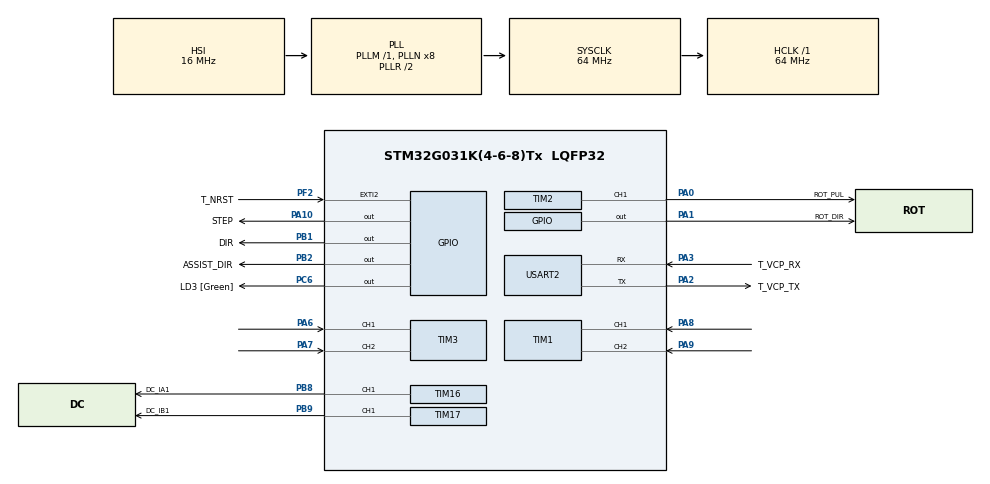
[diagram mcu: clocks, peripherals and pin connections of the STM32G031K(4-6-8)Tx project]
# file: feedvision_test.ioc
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Mcu.Family=STM32G0
Mcu.Name=STM32G031K(4-6-8)Tx
Mcu.Package=LQFP32
NVIC.TIM14_IRQn=true\:0\:0\:false\:false\:true\:true\:true\:true
NVIC.USART2_IRQn=true\:2\:0\:true\:false\:true\:true\:true\:true
PA0.GPIO_Label=ROT_PUL
PA0.GPIO_Speed=GPIO_SPEED_FREQ_HIGH
PA0.Signal=S_TIM2_CH1
PA1.GPIO_Label=ROT_DIR
PA1.GPIO_Speed=GPIO_SPEED_FREQ_HIGH
PA1.Signal=GPIO_Output
PA10.GPIO_Label=STEP
PA10.GPIO_Speed=GPIO_SPEED_FREQ_HIGH
PA10.Signal=GPIO_Output
PA13.GPIO_Label=T_JTMS
PA13.Mode=Serial_Wire
PA13.Signal=SYS_SWDIO
PA14-BOOT0.GPIO_Label=T_JTCK
PA14-BOOT0.Mode=Serial_Wire
PA14-BOOT0.Signal=SYS_SWCLK
PA2.GPIO_Label=T_VCP_TX
PA2.GPIO_PuPd=GPIO_PULLUP
PA2.Mode=Asynchronous
PA2.Signal=USART2_TX
PA3.GPIO_Label=T_VCP_RX
PA3.GPIO_PuPd=GPIO_PULLUP
PA3.Mode=Asynchronous
PA3.Signal=USART2_RX
PA6.GPIO_PuPd=GPIO_PULLUP
PA6.Signal=S_TIM3_CH1
PA7.GPIO_PuPd=GPIO_PULLUP
PA7.Signal=S_TIM3_CH2
PA8.GPIO_PuPd=GPIO_PULLUP
PA8.Signal=S_TIM1_CH1
PA9.GPIO_PuPd=GPIO_PULLUP
PA9.Signal=S_TIM1_CH2
# Yardımcı çift (2x NEMA17 + 2. TB6600): PB0 = LPTIM1_OUT (AF5) PUL, PB2 = GPIO DIR.
# Kodda PB0 açılışta/durdurmada GPIO LOW, "assist" komutunda AF5'e geçer (main.c assist_*).
PB0.GPIO_Label=ASSIST_PUL
PB0.GPIO_Speed=GPIO_SPEED_FREQ_HIGH
PB0.Signal=LPTIM1_OUT
PB1.GPIO_Label=DIR
PB1.GPIO_Speed=GPIO_SPEED_FREQ_HIGH
PB1.Signal=GPIO_Output
PB2.GPIO_Label=ASSIST_DIR
PB2.GPIO_Speed=GPIO_SPEED_FREQ_HIGH
PB2.Signal=GPIO_Output
PB8.GPIO_Label=DC_IA1
PB8.GPIO_Speed=GPIO_SPEED_FREQ_HIGH
PB8.Signal=S_TIM16_CH1
PB9.GPIO_Label=DC_IB1
PB9.GPIO_Speed=GPIO_SPEED_FREQ_HIGH
PB9.Signal=S_TIM17_CH1
PC14-OSC32_IN\ (PC14).Mode=LSE-External-Oscillator
PC14-OSC32_IN\ (PC14).Signal=RCC_OSC32_IN
PC15-OSC32_OUT\ (PC15).Mode=LSE-External-Oscillator
PC15-OSC32_OUT\ (PC15).Signal=RCC_OSC32_OUT
PC6.GPIO_Label=LD3 [Green]
PC6.Signal=GPIO_Output
PF2\ -\ NRST.GPIO_Label=T_NRST
PF2\ -\ NRST.Signal=GPXTI2
ProjectManager.HeapSize=0x200
ProjectManager.StackSize=0x400
ProjectManager.TargetToolchain=STM32CubeIDE
RCC.ADCFreq_Value=64000000
RCC.AHBFreq_Value=64000000
RCC.CortexFreq_Value=64000000
RCC.EXTERNAL_CLOCK_VALUE=12288000
RCC.HCLKFreq_Value=64000000
RCC.HSE_VALUE=8000000
RCC.HSI_VALUE=16000000
RCC.LPTIM1CLockSelection=RCC_LPTIM1CLKSOURCE_PCLK1
RCC.SYSCLKFreq_VALUE=64000000
RCC.SYSCLKSource=RCC_SYSCLKSOURCE_PLLCLK
RCC.VCOOutputFreq_Value=128000000
SH.S_TIM1_CH1.0=TIM1_CH1,Encoder_Interface
SH.S_TIM1_CH2.0=TIM1_CH2,Encoder_Interface
SH.S_TIM3_CH1.0=TIM3_CH1,Encoder_Interface
SH.S_TIM3_CH2.0=TIM3_CH2,Encoder_Interface
SH.S_TIM2_CH1.0=TIM2_CH1,PWM Generation1 CH1
SH.S_TIM16_CH1.0=TIM16_CH1,PWM Generation1 CH1
SH.S_TIM17_CH1.0=TIM17_CH1,PWM Generation1 CH1
# LPTIM1: yardımcı çift PUL (PB0), PCLK1 64 MHz / 64 = 1 MHz tick. ARR/CMP çalışırken
# main.c assist_write_delay() ile yazılır; PRELOAD (UpdateMode=ENDOFPERIOD) glitch'siz güncelleme için şart.
LPTIM1.ClockPrescaler=LPTIM_PRESCALER_DIV64
LPTIM1.TriggerSource=LPTIM_TRIGSOURCE_SOFTWARE
LPTIM1.UpdateMode=LPTIM_UPDATE_ENDOFPERIOD
TIM1.EncoderMode=TIM_ENCODERMODE_TI12
TIM1.IC1Filter=15
TIM1.IC2Filter=15
# TIM14: step darbe üreteci (base/kesme modu) - 22-09-2026'da TIM16'dan
# buraya taşındı, TIM16 DC motor PWM'e ayrıldığı için (backlog #109).
TIM14.Period=499
TIM14.Prescaler=63
# TIM16/TIM17: DC motor PWM (L9110 hız kontrolü), 1 kHz (Prescaler=63,
# Period=999 -> 1 MHz tick / 1000 = 1 kHz). Frekans seçimi datasheet değeri
# DEĞİL, bkz. docs/protocol.md "DC motor PWM" notu.
TIM16.Period=999
TIM16.Prescaler=63
TIM16.Channel-PWM Generation1 CH1=TIM_CHANNEL_1
TIM16.Pulse-PWM Generation1 CH1=0
TIM17.Period=999
TIM17.Prescaler=63
TIM17.Channel-PWM Generation1 CH1=TIM_CHANNEL_1
TIM17.Pulse-PWM Generation1 CH1=0
# TIM2: dönüş ekseni PUL (NEMA17 + TB6600), PA0/TIM2_CH1 donanım PWM, 1 MHz tick.
# Period=999 sadece başlangıç değeri; çalışırken main.c rot_apply_delay() ARR/CCR'yi
# delay_us'e göre yazar (CCR=0 -> darbe yok). ARR preload açık: glitch'siz güncelleme.
TIM2.AutoReloadPreload=TIM_AUTORELOAD_PRELOAD_ENABLE
TIM2.Channel-PWM Generation1 CH1=TIM_CHANNEL_1
TIM2.Period=999
TIM2.Prescaler=63
TIM2.Pulse-PWM Generation1 CH1=0
TIM3.EncoderMode=TIM_ENCODERMODE_TI12
TIM3.IC1Filter=15
TIM3.IC2Filter=15
USART2.VirtualMode-Asynchronous=VM_ASYNC
USART2.WordLength=WORDLENGTH_8B
VP_LPTIM1_VS_LPTIM_counterModeInternalClock.Mode=Counts__internal_clock_event_00
VP_TIM14_VS_ClockSourceINT.Mode=Enable_Timer
VP_TIM16_VS_ClockSourceINT.Mode=Enable_Timer
VP_TIM17_VS_ClockSourceINT.Mode=Enable_Timer
VP_TIM2_VS_ClockSourceINT.Mode=Internal
board=NUCLEO-G031K8

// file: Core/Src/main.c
/* USER CODE BEGIN Header */
/**
  ******************************************************************************
  * @file           : main.c
  * @brief          : Main program body
  ******************************************************************************
  * @attention
  *
  * Copyright (c) 2026 STMicroelectronics.
  * All rights reserved.
  *
  * This software is licensed under terms that can be found in the LICENSE file
  * in the root directory of this software component.
  * If no LICENSE file comes with this software, it is provided AS-IS.
  *
  ******************************************************************************
  */
/* USER CODE END Header */
#include "main.h"

/* USER CODE BEGIN Includes */

#include <string.h>
#include <stdio.h>
#include <stdlib.h>

/* USER CODE END Includes */

/* USER CODE BEGIN PD */

/* --- Pin tanımları -------------------------------------------------------
 * CubeMX'te User Label yazdıysan bu tanımlar zaten üretilmiştir ve aşağıdaki
 * #ifndef blokları atlanır. Yazmadıysan bunlar devreye girer.               */
#ifndef STEP_Pin
  #define STEP_Pin            GPIO_PIN_10
  #define STEP_GPIO_Port      GPIOA
#endif
#ifndef DIR_Pin
  #define DIR_Pin             GPIO_PIN_1
  #define DIR_GPIO_Port       GPIOB
#endif
#ifndef DC_IA1_Pin
  #define DC_IA1_Pin          GPIO_PIN_8
  #define DC_IA1_GPIO_Port    GPIOB
#endif
#ifndef DC_IB1_Pin
  #define DC_IB1_Pin          GPIO_PIN_9
  #define DC_IB1_GPIO_Port    GPIOB
#endif
/* Dönüş ekseni (NEMA17 + TB6600): PUL = PA0 (D/A0, TIM2_CH1 PWM), DIR = PA1 (A1, GPIO) */
#ifndef ROT_PUL_Pin
  #define ROT_PUL_Pin         GPIO_PIN_0
  #define ROT_PUL_GPIO_Port   GPIOA
#endif
#ifndef ROT_DIR_Pin
  #define ROT_DIR_Pin         GPIO_PIN_1
  #define ROT_DIR_GPIO_Port   GPIOA
#endif
/* Yardımcı çift (2x NEMA17 paralel + 2. TB6600): PUL = PB0 (D6, LPTIM1_OUT AF5), DIR = PB2 (D7, GPIO) */
#ifndef ASSIST_PUL_Pin
  #define ASSIST_PUL_Pin       GPIO_PIN_0
  #define ASSIST_PUL_GPIO_Port GPIOB
#endif
#ifndef ASSIST_DIR_Pin
  #define ASSIST_DIR_Pin       GPIO_PIN_2
  #define ASSIST_DIR_GPIO_Port GPIOB
#endif

/* --- Step motor sınırları ------------------------------------------------
 * delay = iki darbe arasındaki toplam süre (mikrosaniye).
 * Alt sınır 20 us: DM556 datasheet'i 200 kHz'e (5 us periyot) kadar cevap
 * verdiğini söylüyor; biz 4 kat güvenlik payı bırakıp 50 kHz'de duruyoruz.
 * Üst sınır 60000 us: timer 1 MHz'de çalıştığı için yarım periyot 65535'i
 * (16 bit sayacın tavanı) geçemez.                                          */
#define STEP_MIN_DELAY_US     20U
#define STEP_MAX_DELAY_US     60000U

/* Rampa (hızlanma/yavaşlama) başlangıç/bitiş gecikmesi: sıfırdan bu HIZLA
 * (yani bu kadar YAVAŞ bir delay ile) başlar, "accel" kadar adımda hedef
 * hıza (komuttaki delay'e) çıkar; hareketin son "accel" adımında da aynı
 * şekilde bu hıza geri iner. Motor+yük değişirse SAHADA burayı ayarla —
 * çok küçük kalırsa yine sıfırdan hızlı kalkış = step kaybı riski sürer,
 * çok büyük kalırsa rampa gereksiz uzun sürer. */
#define STEP_RAMP_START_DELAY_US  2000U

/* --- Encoder / mesafe hesabı sabitleri -----------------------------------
 * SAHADA DOĞRULA: ENC_PPR encoder etiketinden, WHEEL_DIAMETER_MM kumpasla.  */
#define ENC_PPR               600.0f     /* encoder etiketinde yazan darbe/tur */
#define ENC_EDGE_MULTIPLIER   4.0f       /* timer A ve B'nin 4 kenarını da sayar */
#define WHEEL_DIAMETER_MM     40.0f      /* VARSAYIM - gerçek tekerlekle güncelle */

/* --- PC'ye durum gönderme hızı ------------------------------------------- */
#define STATUS_PERIOD_MS      50U        /* 50 ms = saniyede 20 satır */

/* --- Seri porttan gelen komut satırı tamponu ----------------------------- */
#define RX_LINE_MAX            96

/* --- DC motor PWM (L9110 hız kontrolü, backlog #109) ---------------------
 * TIM16/TIM17'yi 1 MHz tick'e böldük (Prescaler=63, 64 MHz APB/64), periyot
 * 1000 tık = 1 ms -> 1 kHz PWM frekansı. 1 kHz seçimi L9110 datasheet'inde
 * yazan bir "optimal PWM frekansı" değil (datasheet'te böyle bir değer YOK,
 * sadece VCC/akım limitleri var) - hobi-seviye DC motor sürücülerinde yaygın
 * kullanılan, motorun elektriksel zaman sabitine göre güvenli bir orta değer.
 * SAHADA DOĞRULA: çok düşük duty'de motor gerçekten dönüyor mu (minimum
 * çalışır duty), ses/ısınma sorunlu mu - gerekirse bu tek satırı değiştir. */
#define DC_PWM_PRESCALER        63U    /* 64 MHz / 64 = 1 MHz tick (1 us) */
#define DC_PWM_PERIOD_TICKS    999U    /* 1000 tık = 1 ms periyot -> 1 kHz PWM */
#define DC_SPEED_DEFAULT_PCT   100U    /* "speed" alanı yoksa eski davranış: tam hız */

/* --- Dönüş ekseni (rot): NEMA17 + TB6600, TIM2_CH1 donanım PWM -------------
 * TIM2 de 1 MHz tick (Prescaler=63), ama burada periyot = delay_us: ARR=delay-1,
 * CCR=delay/2 (%50 doluluk). Dönüş sürekli ve mesafesiz olduğu için darbe SAYMAYA
 * gerek yok -> darbeyi donanım üretir (kesmesiz, jitter'sız). Durdurmak = CCR=0
 * (PWM1'de CCR=0 çıkışı sürekli LOW tutar).
 * delay_us = iki darbe arası süre (step komutundaki delay ile aynı anlam).
 * Alt sınır 100 us = 10 kHz: %50 doluluk -> darbe genişliği 50 us. TB6600 satıcı
 * beyanı üst frekans 50 kHz (Joy-IT SBC-MD-TB6600 datasheet) -> 5 kat pay.
 * Üst sınır 60000 us: RPi ile sabit sözleşme (TIM2 32 bit, teknik olarak daha
 * yavaşı mümkün ama iki taraf senkron kalsın diye YÜKSELTİLMEDİ).
 * Sınırların dışı step komutundaki gibi sessizce kırpılır. */
#define ROT_MIN_DELAY_US        100U
#define ROT_MAX_DELAY_US        60000U
#define ROT_PWM_PRESCALER       63U    /* 64 MHz / 64 = 1 MHz tick (1 us) */
#define ROT_PWM_INIT_PERIOD_TICKS 999U /* sadece başlangıç; çalışırken delay_us'den yazılır */

/* "cw" = motorun MİL UCUNA bakınca saat yönü. DIR pininin hangi seviyesinin cw
 * olduğu kablolamaya (motor bobin polaritesi) bağlı, SAHADA DOĞRULA: ters
 * dönüyorsa SADECE bu satırı GPIO_PIN_RESET yap. */
#define ROT_CW_DIR_LEVEL        GPIO_PIN_SET
#define ROT_CCW_DIR_LEVEL       ((ROT_CW_DIR_LEVEL == GPIO_PIN_SET) ? GPIO_PIN_RESET : GPIO_PIN_SET)

/* Yazılımsal rampa (yumuşak kalkış). Sebep: 100 us (10 kHz = 3.125 tur/s, 1/16
 * mikroadımda) sıfırdan ani başlangıçta NEMA17 senkronu kaybedip dönmeyebilir.
 * Frekans domaininde sabit ivme: START_DELAY'den (1000 us = 1 kHz = ~19 dev/dk)
 * başlar, ACCEL kadar darbe/s^2 ile hedefe çıkar. Hedef START'tan yavaşsa
 * rampa yok, doğrudan hedefte başlar. Hız değişimi ve yön değişimi de aynı
 * rampayı kullanır (yön değişiminde önce START'a iner, DIR çevrilir, tekrar
 * çıkar). stop/reset/bye ise ANINDA keser (güvenlik; konum takibi yok, adım
 * kaybı bir sorun değil). Yük bilinmiyor: SAHADA ayarla - motor kalkışta
 * takılıyorsa ACCEL'i düşür / START_DELAY'i büyüt. */
#define ROT_RAMP_START_DELAY_US     1000U
#define ROT_RAMP_ACCEL_HZ_PER_S     10000U   /* 1 kHz -> 10 kHz yaklaşık 0.9 s */
#define ROT_RAMP_TICK_MS            10U      /* rampa en sık bu aralıkla güncellenir */

/* --- Yardımcı çift (assist): 2x NEMA17 paralel + 2. TB6600, LPTIM1_OUT donanım PWM ---
 * Besleme ekseninde NEMA23'e (step) çubuğa yardım eden iki NEMA17. İki motor aynı
 * yönde döner, tek bir PUL/DIR çifti ikisini birden sürer. Hızı step'ten BAĞIMSIZ,
 * kendi delay'i vardır (oran/çarpan hesabı yok).
 * Darbeyi LPTIM1 donanımı üretir (kesmesiz, jitter'sız; TIM14/encoder/USART2'ye etkisi
 * yok). TIM1/2/3/14/16/17 dolu; PB0'a bağlanabilen tek boş sayaç LPTIM1
 * (PB0 = LPTIM1_OUT, AF5).
 * LPTIM1 çekirdek saati PCLK1 = 64 MHz, önbölücü /64 -> 1 MHz (1 tık = 1 us).
 * ARR = delay-1, çıkış periyodun SONUNDA yüksek: CMP = ARR - delay/2 -> %50 doluluk,
 * darbe genişliği delay/2 (alt sınırda 50 us; TB6600 için >=10 us güvenli minimum).
 * Alt/üst sınır rot ile aynı; ARR 16 bit olduğu için 65536 us'nin altında kalmak şart.
 * Sınırların dışı step/rot komutundaki gibi sessizce kırpılır. */
#define ASSIST_MIN_DELAY_US     100U
#define ASSIST_MAX_DELAY_US     60000U
#define ASSIST_LPTIM_CFGR       (LPTIM_CFGR_PRESC_1 | LPTIM_CFGR_PRESC_2 | LPTIM_CFGR_PRELOAD)  /* /64, değerler periyot sonunda devreye girer */
#define ASSIST_HW_WAIT_LOOPS    20000U   /* ARROK/CMPOK bayrağı için sınırlı bekleme (başlatmada) */
#define ASSIST_HW_TIMEOUT_MS    250U     /* bayrak/periyot sonu bu sürede gelmezse eksen durdurulur (en uzun periyot 60 ms) */

/* "cw" = ortak dönüş yönü. DIR seviyesi kablolamaya bağlı, SAHADA DOĞRULA:
 * ters dönüyorsa SADECE bu satırı GPIO_PIN_RESET yap. */
#define ASSIST_CW_DIR_LEVEL     GPIO_PIN_SET
#define ASSIST_CCW_DIR_LEVEL    ((ASSIST_CW_DIR_LEVEL == GPIO_PIN_SET) ? GPIO_PIN_RESET : GPIO_PIN_SET)

/* Rampa rot ile aynı (ayrı ayarlanabilsin diye ayrı tanım). */
#define ASSIST_RAMP_START_DELAY_US  1000U
#define ASSIST_RAMP_ACCEL_HZ_PER_S  10000U
#define ASSIST_RAMP_TICK_MS         10U

/* USER CODE END PD */

TIM_HandleTypeDef htim1;
TIM_HandleTypeDef htim2;    /* dönüş ekseni PUL (donanım PWM) - PA0/TIM2_CH1 */
TIM_HandleTypeDef htim3;
TIM_HandleTypeDef htim14;   /* step darbe üreteci (base/kesme modu) - eskiden TIM16'daydı */
TIM_HandleTypeDef htim16;   /* DC motor PWM - IA1/PB8 */
TIM_HandleTypeDef htim17;   /* DC motor PWM - IB1/PB9 */

UART_HandleTypeDef huart2;

/* USER CODE BEGIN PV */

/* --- Step darbe üreteci durumu ------------------------------------------
 * "volatile": bu değişkenleri hem ana döngü hem kesme (interrupt) değiştiriyor,
 * derleyiciye "değeri önbelleğe alma, her seferinde bellekten oku" diyoruz.  */
typedef struct {
  volatile uint32_t remaining;  /* atılmayı bekleyen darbe sayısı */
  volatile uint8_t  level;      /* STEP pini şu an 1 mi 0 mı */
  volatile uint8_t  running;    /* 1 = hareket sürüyor */

  /* --- Rampa (hızlanma/yavaşlama) durumu ---------------------------------
   * "delay" artık tek bir sabit değer değil, hareket boyunca değişebiliyor:
   * ilk "accel_steps" adımda start_delay'den cruise_delay'e iner (hızlanma),
   * ortada cruise_delay'de sabit kalır, son "accel_steps" adımda tekrar
   * start_delay'e çıkar (yavaşlama). accel_steps=0 ise rampa YOK, eski
   * davranış: baştan sona sabit cruise_delay (geriye dönük uyumlu). */
  uint32_t total_steps;     /* step_start()'a verilen toplam adım (rampa oranı için) */
  uint32_t cruise_delay_us; /* hedef/komut edilen sabit hız */
  uint32_t start_delay_us;  /* rampa başlangıç/bitiş gecikmesi (yavaş, güvenli) */
  uint32_t accel_steps;     /* kaç adımda hızlanılıp/yavaşlanılacağı */
} step_generator_t;

static step_generator_t g_step = {0, 0, 0};

/* --- Encoder okuma durumu ------------------------------------------------
 * Timer'ın sayacı 16 bit (0..65535) ve dolunca başa dönüyor. Toplam mesafeyi
 * kaybetmemek için her okumada FARKI alıp 32 bitlik bir toplayıcıda biriktiriyoruz. */
typedef struct {
  TIM_HandleTypeDef *htim;
  uint16_t           last_raw;  /* en son okunan 16 bit sayaç değeri */
  int32_t            total;     /* başlangıçtan beri toplam sayım (işaretli) */
} encoder_t;

static encoder_t g_enc1;        /* TIM1 - motorlu tekerlek */
static encoder_t g_enc2;        /* TIM3 - boşta tekerlek */

/* --- DC motor durumu: 0=dur, 1=ileri, 2=geri; hız 0-100 (duty %) --------- */
static uint8_t g_dc_state = 0;
static uint8_t g_dc_speed = 0;

/* --- Dönüş ekseni (rot) durumu -------------------------------------------
 * Hepsi ana döngü bağlamında (process_command + rot_service) değişir, kesme
 * dokunmaz -> volatile gerekmez. */
typedef struct {
  uint8_t  state;            /* komut edilen yön: 0=dur, 1=cw, 2=ccw (durumdaki "rot") */
  uint8_t  phys_state;       /* DIR pininin şu an gerçekten ayarlı olduğu yön (0=henüz ayarlanmadı) */
  uint8_t  pulsing;          /* 1 = PUL çıkışı darbe üretiyor */
  uint8_t  reversing;        /* 1 = yön değişimi için START hızına yavaşlıyor */
  uint32_t target_delay_us;  /* komut edilen (kırpılmış) hedef delay (durumdaki "rdelay") */
  uint32_t cur_delay_us;     /* o anki gerçek darbe periyodu (rampa ortasında hedeften yavaş) */
  uint32_t last_ramp_ms;     /* rampanın son güncellendiği HAL_GetTick */
} rot_axis_t;

static rot_axis_t g_rot = {0, 0, 0, 0, 0, 0, 0};

/* --- Yardımcı çift (assist) durumu ----------------------------------------
 * rot ile aynı alanlar + LPTIM yazma bayrağı beklemesi. Kesme dokunmaz (LPTIM
 * kesmesi kapalı) -> volatile gerekmez. */
typedef struct {
  uint8_t  state;            /* komut edilen yön: 0=dur, 1=cw, 2=ccw (durumdaki "assist") */
  uint8_t  phys_state;       /* DIR pininin şu an gerçekten ayarlı olduğu yön (0=henüz ayarlanmadı) */
  uint8_t  pulsing;          /* 1 = LPTIM1 çalışıyor, PB0 darbe üretiyor */
  uint8_t  reversing;        /* 1 = yön değişimi için START hızına yavaşlıyor */
  uint8_t  reg_pending;      /* 1 = ARR/CMP yazıldı, ARROK+CMPOK bayrakları bekleniyor */
  uint32_t target_delay_us;  /* komut edilen (kırpılmış) hedef delay (durumdaki "adelay") */
  uint32_t cur_delay_us;     /* o anki gerçek darbe periyodu */
  uint32_t last_ramp_ms;     /* rampanın son güncellendiği HAL_GetTick */
  uint32_t reg_write_ms;     /* ARR/CMP son yazıldığı HAL_GetTick (zaman aşımı için) */
} assist_axis_t;

static assist_axis_t g_assist = {0, 0, 0, 0, 0, 0, 0, 0, 0};

/* --- Seri port alım tamponları ------------------------------------------ */
static uint8_t           g_rx_byte;                    /* kesmede tek tek gelen karakter */
static char               g_rx_line[RX_LINE_MAX];      /* birikmekte olan satır */
static volatile uint16_t g_rx_length = 0;
static char               g_command[RX_LINE_MAX];      /* tamamlanmış komut satırı */
static volatile uint8_t  g_command_ready = 0;

/* --- Durum gönderme zamanlayıcısı --------------------------------------- */
static uint32_t g_last_status_ms = 0;

/* --- LED ile bağlantı doğrulaması ----------------------------------------
 * host_confirmed: Pi/Mac'ten geçerli bir komut alınca 1 olur. LED'i
 * yavaş/hızlı yanıp söndürmek için kullanılır (bkz. USER CODE 3): yavaş =
 * "firmware çalışıyor ama kimse konuşmadı / bağlantı koptu", hızlı = "gerçek
 * bir komut alındı, karşı taraf bağlı". Host bağlantının koptuğuna karar
 * verince "bye" komutunu gönderir (bkz. process_command) — bu bayrağı tekrar
 * 0'a çeker, LED yavaş moda döner (22-09-2026, LED tek-yön latch düzeltmesi). */
static volatile uint8_t g_host_confirmed = 0;
static uint16_t          g_led_tick = 0;

/* USER CODE END PV */

void SystemClock_Config(void);
static void MX_GPIO_Init(void);
static void MX_TIM1_Init(void);
static void MX_LPTIM1_Init(void);
static void MX_TIM2_Init(void);
static void MX_TIM3_Init(void);
static void MX_TIM14_Init(void);
static void MX_TIM16_Init(void);
static void MX_TIM17_Init(void);
static void MX_USART2_UART_Init(void);
/* USER CODE BEGIN PFP */

/* --- Encoder fonksiyonları --- */
static void     encoder_init(encoder_t *e, TIM_HandleTypeDef *htim);   // encoder'ı sıfırdan başlatır (donanım sayacını çalıştırır)
static void     encoder_update(encoder_t *e);                          // sayacı okuyup toplam mesafeye ekler (periyodik çağrılır)
static void     encoder_reset(encoder_t *e);                           // sayacı ve toplamı 0'a resetler
static int32_t  encoder_to_micrometers(int32_t count);                 // ham sayımı mikrometreye (mm'nin 1000'de biri) çevirir

/* --- Step motor fonksiyonları --- */
static void     step_start(uint8_t dir, uint32_t count, uint32_t delay_us, uint32_t accel_steps);  // step motoru başlatır: yön + kaç adım + ne hızda + kaç adımda hızlan/yavaşla
static uint32_t step_delay_for_remaining(uint32_t remaining);  // rampanın o anki fazına göre gecikme hesaplar
static void     step_stop(void);                                              // step motoru anında durdurur

/* --- DC motor fonksiyonu --- */
static uint16_t dc_duty_ticks(uint8_t speed_pct);       // 0-100 yüzdeyi timer CCR tık değerine çevirir
static void     dc_set(uint8_t state, uint8_t speed_pct);  // DC motoru ileri/geri/dur + hız (PWM duty %) durumuna sokar

/* --- Dönüş ekseni (NEMA17 + TB6600) fonksiyonları --- */
static uint32_t rot_next_delay(uint32_t cur_us, uint32_t goal_us, uint32_t dt_ms);  // rampada bir sonraki darbe periyodunu hesaplar (saf fonksiyon)
static void     rot_apply_delay(uint32_t delay_us);                                 // TIM2 periyodunu/dolulugunu delay_us'e ayarlar
static void     rot_begin(uint8_t dir_state);                                       // DIR'i ayarlayıp darbeyi rampa başlangıç hızıyla başlatır
static void     rot_halt_pulses(void);                                              // PUL çıkışını anında LOW'a çeker (durum alanlarına dokunmaz)
static void     rot_stop(void);                                                     // dönüş eksenini anında durdurur (stop/reset/bye de bunu çağırır)
static void     rot_command(uint8_t dir_state, uint32_t delay_us);                  // "rot" komutu: başlat / hız değiştir / yön değiştir
static void     rot_service(void);                                                  // ana döngüden periyodik çağrılır: rampayı ilerletir

/* --- Yardımcı çift (2x NEMA17 + 2. TB6600, LPTIM1) fonksiyonları --- */
static uint32_t ramp_next_delay(uint32_t cur_us, uint32_t goal_us, uint32_t dt_ms, uint32_t accel_hz_per_s);  // rampada bir sonraki darbe periyodu (saf fonksiyon, rot ve assist ortak)
static void     assist_pul_gpio_low(void);                                          // PB0'ı GPIO çıkışı yapıp anında LOW'a çeker
static void     assist_pul_af(void);                                                // PB0'ı LPTIM1_OUT (AF5) yapar
static void     assist_write_delay(uint32_t delay_us);                              // LPTIM1 ARR/CMP'yi delay_us'e göre yazar
static uint8_t  assist_wait_flags(uint32_t mask);                                   // ISR bayraklarını sınırlı süre bekler (1=geldi)
static void     assist_halt_pulses(void);                                           // PB0 LOW + LPTIM1 reset (durum alanlarına dokunmaz)
static void     assist_stop(void);                                                  // yardımcı çifti anında durdurur (stop/reset/bye de bunu çağırır)
static uint8_t  assist_begin(uint8_t dir_state);                                    // DIR'i ayarlayıp darbeyi rampa başlangıç hızıyla başlatır (0=donanım hatası)
static uint8_t  assist_command(uint8_t dir_state, uint32_t delay_us);               // "assist" komutu: başlat / hız değiştir / yön değiştir (0=donanım hatası)
static void     assist_service(void);                                               // ana döngüden periyodik çağrılır: rampayı ilerletir

/* --- Seri port (UART) fonksiyonları --- */
static void     uart_send(const char *s);              // bir metni Mac'e (seri port üzerinden) gönderir
static void     send_status(void);                      // encoder/motor durumunu JSON olarak Mac'e yollar
static void     process_command(const char *line);      // Mac'ten gelen bir JSON komut satırını yorumlayıp uygular

/* --- JSON okuma yardımcıları (kütüphanesiz, elle yazılmış basit ayrıştırıcı) --- */
static int      json_read_int(const char *json, const char *key, int32_t *out);                 // JSON'dan bir sayı değeri çeker (örn: "delay":500)
static int      json_read_str(const char *json, const char *key, char *out, uint16_t out_size);  // JSON'dan bir metin değeri çeker (örn: "cmd":"step")

/* USER CODE END PFP */

/* USER CODE BEGIN 0 */

/* ==========================================================================
 *  ENCODER  —  sayaç okuma ve mesafeye çevirme
 * ========================================================================== */

static void encoder_init(encoder_t *e, TIM_HandleTypeDef *htim)
{
  e->htim = htim;
  HAL_TIM_Encoder_Start(htim, TIM_CHANNEL_ALL);   /* donanım saymaya başlasın */
  __HAL_TIM_SET_COUNTER(htim, 0);
  e->last_raw = 0;
  e->total    = 0;
}

/* Ana döngüde periyodik çağrılır. 16 bit sayacın taşmasını doğru şekilde işler. */
static void encoder_update(encoder_t *e)
{
  uint16_t raw = (uint16_t)__HAL_TIM_GET_COUNTER(e->htim);

  /* İki 16 bit sayının farkını int16_t olarak almak, sayaç 65535'ten 0'a
   * atladığında da doğru sonucu verir (ör: 5 - 65530 = 11, geriye değil ileriye). */
  int16_t diff = (int16_t)(raw - e->last_raw);

  e->last_raw  = raw;
  e->total    += (int32_t)diff;
}

static void encoder_reset(encoder_t *e)
{
  __HAL_TIM_SET_COUNTER(e->htim, 0);
  e->last_raw = 0;
  e->total    = 0;
}

/* --------------------------------------------------------------------------
 *  5 mm'lik mesafe nasıl hesaplanıyor  (asıl istenen mantık burada)
 * --------------------------------------------------------------------------
 *  1) Encoder bir turda kaç sayım üretir?
 *        counts_per_rev = ENC_PPR * 4 = 600 * 4 = 2400
 *     ("* 4" nereden geliyor: timer'ı "Encoder Mode TI1 and TI2" kurduk, yani
 *      A kanalının hem yükselen hem düşen kenarını, B kanalının da ikisini
 *      sayıyor. Böylece çözünürlük 4 katına çıkıyor.)
 *
 *  2) Tekerlek bir turda kaç mm yol alır?
 *        circumference_mm = pi * WHEEL_DIAMETER_MM = 3.14159 * 40.0 = 125.664 mm
 *
 *  3) Bir sayım kaç mm eder?
 *        mm_per_count = 125.664 / 2400 = 0.05236 mm  (yani 52.36 mikrometre)
 *
 *  4) 5 mm ilerlemek için kaç sayım gerekir?
 *        5.0 / 0.05236 = 95.5 count
 *     Yani "5 mm ilerledi" demek icin encoder sayacinin ~96 artmasi lazim.
 *     Bu, 5 mm'lik bir olcumu +/- 0.05 mm hassasiyetle gorebiliyoruz demek —
 *     bu uygulama icin fazlasiyla yeterli.
 *
 *  5) Patinaj (kayma) tespiti:
 *        Encoder 1 = motorlu tekerlek, Encoder 2 = bosta klavuz tekerlek.
 *        Ikisi ayni cubugu olcuyor. Aralarindaki mm farki = kayan miktar.
 *        Fark buyurse cubuk motorun altinda patinaj yapiyor demektir.
 *
 *  NOT: WHEEL_DIAMETER_MM su an 40.0 mm VARSAYIM. Gercek tekerlek gelince
 *       olcup degistir, yoksa buradaki tum mm degerleri orantili sekilde
 *       yanlis olur.
 * -------------------------------------------------------------------------- */

/* Sayımı mikrometreye çevirir.
 * Neden mm değil mikrometre: CubeIDE varsayılan ayarında printf ondalık sayı
 * basamıyor (%f çöp üretir). Tam sayı gönderip PC'de 1000'e bölüyoruz. */
static int32_t encoder_to_micrometers(int32_t count)
{
  const float counts_per_rev   = ENC_PPR * ENC_EDGE_MULTIPLIER;         /* 2400 */
  const float circumference_um = 3.14159265f * WHEEL_DIAMETER_MM * 1000.0f; /* 125663.7 um */
  const float um_per_count     = circumference_um / counts_per_rev;     /* 52.36 um */

  return (int32_t)((float)count * um_per_count);
}

/* ==========================================================================
 *  STEP MOTOR  —  TIM14 kesmesi ile sabit hızda darbe üretimi
 *  (22-09-2026: DC motor PWM eklenirken TIM16'dan TIM14'e taşındı - bkz.
 *  main.c başındaki "DC motor PWM" bölümü ve INSA_GUNLUGU.md notu.)
 * ========================================================================== */

/* Şu anki adımda (remaining kaç darbe kaldıysa) kullanılması gereken
 * gecikmeyi hesaplar — rampanın hızlanma/sabit/yavaşlama neresinde
 * olduğumuza bakar. ISR içinden de çağrıldığı için basit tam sayı
 * matematiği dışında bir şey yapmaz (float/bölme dışı ağır işlem yok). */
static uint32_t step_delay_for_remaining(uint32_t remaining)
{
  uint32_t done = g_step.total_steps - remaining;   /* şu ana kadar atılan darbe */

  if (g_step.accel_steps == 0U) {
    return g_step.cruise_delay_us;                  /* rampa yok - eski davranış */
  }
  if (done < g_step.accel_steps) {
    /* Hızlanma: start_delay'den cruise_delay'e doğrusal iniyor. */
    uint32_t span = g_step.start_delay_us - g_step.cruise_delay_us;
    return g_step.start_delay_us - (span * done / g_step.accel_steps);
  }
  if (remaining <= g_step.accel_steps) {
    /* Yavaşlama: cruise_delay'den start_delay'e doğrusal çıkıyor (simetrik). */
    uint32_t span = g_step.start_delay_us - g_step.cruise_delay_us;
    return g_step.start_delay_us - (span * remaining / g_step.accel_steps);
  }
  return g_step.cruise_delay_us;                     /* rampalar arası - sabit hız */
}

/* dir         : 0 veya 1 (DIR pininin seviyesi)
 * count       : atılacak tam darbe sayısı
 * delay_us    : hedef/sabit hız - iki darbe arası toplam süre (mikrosaniye), küçük değer = hızlı
 * accel_steps : hızlanıp yavaşlanacağı adım sayısı (0 = rampasız, eski davranış) */
static void step_start(uint8_t dir, uint32_t count, uint32_t delay_us, uint32_t accel_steps)
{
  if (count == 0U) {
    return;
  }

  /* Kullanıcı saçma bir hız girerse sınırların içine çek */
  if (delay_us < STEP_MIN_DELAY_US) delay_us = STEP_MIN_DELAY_US;
  if (delay_us > STEP_MAX_DELAY_US) delay_us = STEP_MAX_DELAY_US;

  /* Rampa toplam adımın yarısından fazlasını isteyemez (hızlanma+yavaşlama
   * çakışmasın diye) - kısa hareketlerde otomatik küçültülür. */
  if (accel_steps > count / 2U) accel_steps = count / 2U;

  step_stop();   /* önceki hareket varsa temizle */

  /* Yön pinini darbelerden ÖNCE ayarla, sürücünün okuması için 1 ms bekle */
  HAL_GPIO_WritePin(DIR_GPIO_Port, DIR_Pin, dir ? GPIO_PIN_SET : GPIO_PIN_RESET);
  HAL_Delay(1);

  HAL_GPIO_WritePin(STEP_GPIO_Port, STEP_Pin, GPIO_PIN_RESET);
  g_step.level           = 0;
  g_step.remaining       = count;
  g_step.total_steps     = count;
  g_step.cruise_delay_us = delay_us;
  g_step.accel_steps     = accel_steps;
  /* Rampa başlangıcı hedeften daha YAVAŞ olmalı (büyük delay); komut edilen
   * hız zaten rampa başlangıcından yavaşsa (delay_us >= start delay), rampa
   * yapılacak bir şey yok - fiilen accel_steps=0 gibi davranır. */
  g_step.start_delay_us  = (STEP_RAMP_START_DELAY_US > delay_us) ? STEP_RAMP_START_DELAY_US : delay_us;
  g_step.running         = 1;

  /* Timer 1 MHz'de sayıyor (Prescaler=63 ayarladık), yani 1 tık = 1 us.
   * Kesme her YARIM periyotta bir gelecek: bir kesmede pini kaldır, sonrakinde indir.
   * Böylece tam bir darbe delay_us kadar sürer. İlk darbe rampa başlangıç
   * hızıyla (ya da rampasızsa doğrudan cruise hızıyla) başlıyor. */
  __HAL_TIM_SET_AUTORELOAD(&htim14, (step_delay_for_remaining(count) / 2U) - 1U);
  __HAL_TIM_SET_COUNTER(&htim14, 0);
  __HAL_TIM_CLEAR_FLAG(&htim14, TIM_FLAG_UPDATE);  /* bekleyen eski bayrağı sil */

  HAL_TIM_Base_Start_IT(&htim14);
}

static void step_stop(void)
{
  HAL_TIM_Base_Stop_IT(&htim14);
  g_step.running   = 0;
  g_step.remaining = 0;
  g_step.level     = 0;
  HAL_GPIO_WritePin(STEP_GPIO_Port, STEP_Pin, GPIO_PIN_RESET);
}

/* ==========================================================================
 *  DC MOTOR  —  L9110, PWM ile yavaş/hızlı sürüş (22-09-2026, backlog #109)
 * ========================================================================== */

/* L9110'da ayrı bir "enable" pini yok - hız kontrolü aktif yöndeki pine PWM
 * uygulanarak yapılır, diğer pin sabit LOW (duty=0) kalır:
 *   IA1=PWM(duty), IB1=0   -> forward (ileri), hız = duty
 *   IA1=0,         IB1=PWM(duty) -> backward (geri), hız = duty
 *   IA1=0,         IB1=0   -> stop (dur)
 * (İkisini birden aktif/HIGH yapmak yasak - sürücüyü kısa devre eder; bu
 * fonksiyon her zaman diğer kanalı 0'a çektiği için bu durum oluşmaz.)
 * PB8=TIM16_CH1, PB9=TIM17_CH1 - ikisi de artık AF-PWM modunda (bkz.
 * MX_TIM16_Init/MX_TIM17_Init), GPIO_MODE_OUTPUT_PP DEĞİL. */
static uint16_t dc_duty_ticks(uint8_t speed_pct)
{
  if (speed_pct > 100U) speed_pct = 100U;
  /* (period+1) tık = 1 PWM periyodu; speed_pct=100 -> tam periyot (sürekli HIGH) */
  return (uint16_t)(((uint32_t)speed_pct * (DC_PWM_PERIOD_TICKS + 1U)) / 100U);
}

static void dc_set(uint8_t state, uint8_t speed_pct)
{
  uint16_t duty = dc_duty_ticks(speed_pct);

  switch (state) {
    case 1: /* forward */
      __HAL_TIM_SET_COMPARE(&htim16, TIM_CHANNEL_1, duty);
      __HAL_TIM_SET_COMPARE(&htim17, TIM_CHANNEL_1, 0U);
      break;
    case 2: /* backward */
      __HAL_TIM_SET_COMPARE(&htim16, TIM_CHANNEL_1, 0U);
      __HAL_TIM_SET_COMPARE(&htim17, TIM_CHANNEL_1, duty);
      break;
    default: /* stop */
      __HAL_TIM_SET_COMPARE(&htim16, TIM_CHANNEL_1, 0U);
      __HAL_TIM_SET_COMPARE(&htim17, TIM_CHANNEL_1, 0U);
      state = 0;
      speed_pct = 0;
      break;
  }
  g_dc_state = state;
  g_dc_speed = (state == 0U) ? 0U : (speed_pct > 100U ? 100U : speed_pct);
}

/* ==========================================================================
 *  DÖNÜŞ EKSENİ  —  NEMA17 + TB6600, PUL = TIM2_CH1 donanım PWM (PA0)
 *  DIR = PA1 (GPIO). ENA bağlanmaz (TB6600'de ENA aktifse motor serbest kalır,
 *  boş bırakınca sürücü hep aktif = duruşta tutma torku var).
 * ========================================================================== */

/* Rampada bir sonraki darbe periyodu. Sabit İVME frekans domaininde: f = 1e6/delay,
 * f += ACCEL * dt, yeni delay = 1e6/f. goal'a asla taşmaz. Saf fonksiyon (donanıma
 * dokunmaz). Her çağrıda en az 1 us ilerler, yani sonlu adımda goal'a ulaşır. */
static uint32_t ramp_next_delay(uint32_t cur_us, uint32_t goal_us, uint32_t dt_ms, uint32_t accel_hz_per_s)
{
  uint32_t inc;
  uint32_t freq;
  uint32_t next;

  if (cur_us == 0U || cur_us == goal_us) {
    return goal_us;
  }

  inc  = (accel_hz_per_s * dt_ms) / 1000U;            /* bu aralıkta eklenecek frekans (Hz) */
  freq = 1000000U / cur_us;

  if (goal_us < cur_us) {
    /* Hızlan (delay küçülür, frekans artar) */
    next = 1000000U / (freq + inc);
    if (next >= cur_us)  next = cur_us - 1U;           /* tamsayı bölme yüzünden takılmasın */
    if (next < goal_us)  next = goal_us;
  } else {
    /* Yavaşla (delay büyür, frekans azalır) */
    if (inc >= freq) {
      next = goal_us;
    } else {
      next = 1000000U / (freq - inc);
      if (next <= cur_us)  next = cur_us + 1U;
      if (next > goal_us)  next = goal_us;
    }
  }
  return next;
}

static uint32_t rot_next_delay(uint32_t cur_us, uint32_t goal_us, uint32_t dt_ms)
{
  return ramp_next_delay(cur_us, goal_us, dt_ms, ROT_RAMP_ACCEL_HZ_PER_S);
}

/* Darbe periyodunu delay_us yapar: ARR=delay-1, CCR=delay/2 (%50). ARR preload
 * açık (MX_TIM2_Init) ve CCR preload HAL'da açık -> yeni değerler bir sonraki
 * periyot sınırında birlikte devreye girer, yarım darbe/glitch oluşmaz. */
static void rot_apply_delay(uint32_t delay_us)
{
  __HAL_TIM_SET_AUTORELOAD(&htim2, delay_us - 1U);
  __HAL_TIM_SET_COMPARE(&htim2, TIM_CHANNEL_1, delay_us / 2U);
}

/* PUL'u anında LOW'a çeker: CCR=0 (PWM1'de çıkış sürekli LOW) + UG olayı ile
 * preload'u hemen yükler ve sayacı sıfırlar (yoksa CCR=0 bir sonraki periyot
 * sınırına kadar, 60 ms'ye kadar gecikebilir). */
static void rot_halt_pulses(void)
{
  __HAL_TIM_SET_COMPARE(&htim2, TIM_CHANNEL_1, 0U);
  htim2.Instance->EGR = TIM_EGR_UG;
  g_rot.pulsing   = 0U;
  g_rot.reversing = 0U;
}

static void rot_stop(void)
{
  rot_halt_pulses();
  g_rot.state           = 0U;
  g_rot.target_delay_us = 0U;
  g_rot.cur_delay_us    = 0U;
}

/* Darbeleri durmuş halden başlatır. Önce gerekiyorsa DIR'i çevirir ve TB6600'ün
 * yönü okuması için 1 ms bekler (step_start ile aynı pratik; TB6600 için gereken
 * DIR kurulma süresi µs mertebesinde, 1 ms fazlasıyla yeterli). Sonra hedeften
 * yavaş olan rampa başlangıç hızıyla ilk darbeyi hemen üretir (UG: sayaç 0,
 * CCR>0 -> çıkış HIGH ile başlar, tam genişlikte ilk darbe). */
static void rot_begin(uint8_t dir_state)
{
  uint32_t start_us = (g_rot.target_delay_us > ROT_RAMP_START_DELAY_US)
                      ? g_rot.target_delay_us : ROT_RAMP_START_DELAY_US;

  if (g_rot.phys_state != dir_state) {
    HAL_GPIO_WritePin(ROT_DIR_GPIO_Port, ROT_DIR_Pin,
                      (dir_state == 1U) ? ROT_CW_DIR_LEVEL : ROT_CCW_DIR_LEVEL);
    HAL_Delay(1);
    g_rot.phys_state = dir_state;
  }

  g_rot.cur_delay_us = start_us;
  g_rot.reversing    = 0U;
  g_rot.pulsing      = 1U;
  g_rot.last_ramp_ms = HAL_GetTick();
  rot_apply_delay(start_us);
  htim2.Instance->EGR = TIM_EGR_UG;
}

/* "rot" komutunun çekirdeği. dir_state: 0=dur, 1=cw, 2=ccw. delay_us hedef hız
 * (kırpma burada). Çalışırken tekrar gelen komut = hız/yön güncellemesi. */
static void rot_command(uint8_t dir_state, uint32_t delay_us)
{
  if (dir_state == 0U) {
    rot_stop();
    return;
  }

  if (delay_us < ROT_MIN_DELAY_US) delay_us = ROT_MIN_DELAY_US;
  if (delay_us > ROT_MAX_DELAY_US) delay_us = ROT_MAX_DELAY_US;

  g_rot.state           = dir_state;
  g_rot.target_delay_us = delay_us;

  if (!g_rot.pulsing) {
    rot_begin(dir_state);                    /* duruyordu: rampa başlangıcından kalk */
  } else if (dir_state == g_rot.phys_state) {
    g_rot.reversing = 0U;                    /* aynı yön: sadece yeni hedefe rampa */
  } else if (g_rot.cur_delay_us >= ROT_RAMP_START_DELAY_US) {
    rot_halt_pulses();                       /* zaten START'tan yavaş: beklemeden çevir */
    rot_begin(dir_state);
  } else {
    g_rot.reversing = 1U;                    /* hızlı dönüyor: önce START'a yavaşla */
  }
}

/* Ana döngüden her turda çağrılır; ROT_RAMP_TICK_MS'de bir rampayı ilerletir.
 * Gerçek geçen süreyi (dt) kullanır: ana döngü UART gönderirken ~13 ms
 * bloklanabiliyor, sabit adım varsaysak rampa o kadar yavaşlardı. */
static void rot_service(void)
{
  uint32_t now = HAL_GetTick();
  uint32_t dt  = now - g_rot.last_ramp_ms;
  uint32_t goal;

  if (!g_rot.pulsing || dt < ROT_RAMP_TICK_MS) {
    return;
  }
  g_rot.last_ramp_ms = now;
  if (dt > 100U) dt = 100U;                  /* uzun duraksamada tek seferde büyük sıçrama olmasın */

  goal = g_rot.reversing ? ROT_RAMP_START_DELAY_US : g_rot.target_delay_us;

  if (g_rot.cur_delay_us != goal) {
    g_rot.cur_delay_us = rot_next_delay(g_rot.cur_delay_us, goal, dt);
    rot_apply_delay(g_rot.cur_delay_us);
  }

  if (g_rot.reversing && g_rot.cur_delay_us >= ROT_RAMP_START_DELAY_US) {
    rot_halt_pulses();                       /* START hızına indi: DIR'i çevir, yeniden kalk */
    rot_begin(g_rot.state);
  }
}

/* ==========================================================================
 *  YARDIMCI ÇİFT (assist)  —  2x NEMA17 paralel + 2. TB6600, PUL = LPTIM1_OUT (PB0)
 *  DIR = PB2 (GPIO). ENA bağlanmaz (rot ile aynı).
 *  Mantık rot ile aynı; fark: PWM TIM2 yerine LPTIM1, durdurma "CCR=0" yerine
 *  "PB0'ı GPIO LOW yap + LPTIM1'i RCC reset ile sıfırla" (LPTIM'de %0 doluluk yok).
 * ========================================================================== */

/* PB0'ı düz GPIO çıkışı yapıp LOW'a çeker. ODR önce 0 yapılır, sonra mod değişir:
 * AF -> GPIO geçişinde pin hiç yükselmez (stop anında LOW garantisi LPTIM'in boştaki
 * çıkış seviyesine bağlı değil). */
static void assist_pul_gpio_low(void)
{
  GPIO_InitTypeDef gpio = {0};

  HAL_GPIO_WritePin(ASSIST_PUL_GPIO_Port, ASSIST_PUL_Pin, GPIO_PIN_RESET);
  gpio.Pin   = ASSIST_PUL_Pin;
  gpio.Mode  = GPIO_MODE_OUTPUT_PP;
  gpio.Pull  = GPIO_NOPULL;
  gpio.Speed = GPIO_SPEED_FREQ_HIGH;
  HAL_GPIO_Init(ASSIST_PUL_GPIO_Port, &gpio);
}

/* PB0'ı LPTIM1_OUT'a (AF5) verir. Yalnızca LPTIM1 periyot başında (çıkış LOW) iken çağrılır. */
static void assist_pul_af(void)
{
  GPIO_InitTypeDef gpio = {0};

  gpio.Pin       = ASSIST_PUL_Pin;
  gpio.Mode      = GPIO_MODE_AF_PP;
  gpio.Pull      = GPIO_NOPULL;
  gpio.Speed     = GPIO_SPEED_FREQ_HIGH;
  gpio.Alternate = GPIO_AF5_LPTIM1;
  HAL_GPIO_Init(ASSIST_PUL_GPIO_Port, &gpio);
}

/* Periyodu delay_us yapar: ARR=delay-1, CMP=ARR-delay/2 (çıkış CMP'den ARR'a kadar
 * yüksek = delay/2 tık). CMP < ARR her zaman sağlanır (delay >= 2). Hem ARR hem CMP
 * PRELOAD ile periyot sonunda birlikte devreye girer, yarım darbe/glitch oluşmaz.
 * Aynı yazmacı ARROK/CMPOK gelmeden tekrar yazmak "unpredictable" (ST LL notu). */
static void assist_write_delay(uint32_t delay_us)
{
  uint32_t arr = delay_us - 1U;

  LPTIM1->ARR = arr;
  LPTIM1->CMP = arr - (delay_us / 2U);
}

/* ISR'daki bayrakların (mask'in hepsi) gelmesini sınırlı bekler. 1 = geldi, 0 = zaman aşımı. */
static uint8_t assist_wait_flags(uint32_t mask)
{
  uint32_t loops = ASSIST_HW_WAIT_LOOPS;

  while ((LPTIM1->ISR & mask) != mask) {
    if (loops-- == 0U) {
      return 0U;
    }
  }
  return 1U;
}

/* Darbeyi anında keser: önce PB0 GPIO LOW, sonra LPTIM1 RCC reset (tüm yazmaçlar
 * varsayılana, sayaç durur). Yeniden başlatmada CFGR/ARR/CMP baştan yazılır. */
static void assist_halt_pulses(void)
{
  assist_pul_gpio_low();
  __HAL_RCC_LPTIM1_FORCE_RESET();
  __HAL_RCC_LPTIM1_RELEASE_RESET();
  g_assist.pulsing     = 0U;
  g_assist.reversing   = 0U;
  g_assist.reg_pending = 0U;
}

static void assist_stop(void)
{
  assist_halt_pulses();
  g_assist.state           = 0U;
  g_assist.target_delay_us = 0U;
  g_assist.cur_delay_us    = 0U;
}

/* Darbeleri durmuş halden başlatır. Önce gerekiyorsa DIR'i çevirir (1 ms bekler, rot
 * ile aynı). Sonra LPTIM1'i kurar: CFGR (devre dışıyken) -> ENABLE -> ARR/CMP (ENABLE'dan
 * SONRA yazılır) -> ARROK/CMPOK -> sürekli sayım başlat. PB0 ilk periyot sonuna kadar
 * GPIO LOW kalır; ARRM (periyot sonu) görülünce sayaç ~0'dadır ve çıkış LOW'dur, bu
 * anda AF'e geçmek glitch'siz (yarım darbe yok). Hedef START'tan yavaşsa doğrudan hedefte
 * başlar. Dönüş 0 = donanım bayrağı gelmedi (eksen durdurulmuş halde bırakılır). */
static uint8_t assist_begin(uint8_t dir_state)
{
  uint32_t start_us = (g_assist.target_delay_us > ASSIST_RAMP_START_DELAY_US)
                      ? g_assist.target_delay_us : ASSIST_RAMP_START_DELAY_US;
  uint32_t t0;

  if (g_assist.phys_state != dir_state) {
    HAL_GPIO_WritePin(ASSIST_DIR_GPIO_Port, ASSIST_DIR_Pin,
                      (dir_state == 1U) ? ASSIST_CW_DIR_LEVEL : ASSIST_CCW_DIR_LEVEL);
    HAL_Delay(1);
    g_assist.phys_state = dir_state;
  }

  assist_halt_pulses();                      /* temiz başlangıç: PB0 LOW, LPTIM1 varsayılan */

  LPTIM1->CFGR = ASSIST_LPTIM_CFGR;
  LPTIM1->CR   = LPTIM_CR_ENABLE;
  LPTIM1->ICR  = LPTIM_ICR_ARROKCF | LPTIM_ICR_CMPOKCF | LPTIM_ICR_ARRMCF;
  assist_write_delay(start_us);
  if (!assist_wait_flags(LPTIM_ISR_ARROK | LPTIM_ISR_CMPOK)) {
    assist_halt_pulses();
    return 0U;
  }
  LPTIM1->ICR = LPTIM_ICR_ARROKCF | LPTIM_ICR_CMPOKCF | LPTIM_ICR_ARRMCF;
  LPTIM1->CR |= LPTIM_CR_CNTSTRT;

  /* İlk periyot sonunu bekle (sıkı döngü: gecikme birkaç us, CMP en az 49 tık sonra) */
  t0 = HAL_GetTick();
  while ((LPTIM1->ISR & LPTIM_ISR_ARRM) == 0U) {
    if ((HAL_GetTick() - t0) > ASSIST_HW_TIMEOUT_MS) {
      assist_halt_pulses();
      return 0U;
    }
  }
  LPTIM1->ICR = LPTIM_ICR_ARRMCF;
  assist_pul_af();

  g_assist.cur_delay_us = start_us;
  g_assist.reversing    = 0U;
  g_assist.pulsing      = 1U;
  g_assist.last_ramp_ms = HAL_GetTick();
  return 1U;
}

/* "assist" komutunun çekirdeği. dir_state: 0=dur, 1=cw, 2=ccw. delay_us hedef hız
 * (kırpma burada). Çalışırken tekrar gelen komut = hız/yön güncellemesi (rot ile aynı). */
static uint8_t assist_command(uint8_t dir_state, uint32_t delay_us)
{
  if (dir_state == 0U) {
    assist_stop();
    return 1U;
  }

  if (delay_us < ASSIST_MIN_DELAY_US) delay_us = ASSIST_MIN_DELAY_US;
  if (delay_us > ASSIST_MAX_DELAY_US) delay_us = ASSIST_MAX_DELAY_US;

  g_assist.state           = dir_state;
  g_assist.target_delay_us = delay_us;

  if (!g_assist.pulsing) {
    if (!assist_begin(dir_state)) {          /* duruyordu: rampa başlangıcından kalk */
      assist_stop();
      return 0U;
    }
  } else if (dir_state == g_assist.phys_state) {
    g_assist.reversing = 0U;                 /* aynı yön: sadece yeni hedefe rampa */
  } else if (g_assist.cur_delay_us >= ASSIST_RAMP_START_DELAY_US) {
    assist_halt_pulses();                    /* zaten START'tan yavaş: beklemeden çevir */
    if (!assist_begin(dir_state)) {
      assist_stop();
      return 0U;
    }
  } else {
    g_assist.reversing = 1U;                 /* hızlı dönüyor: önce START'a yavaşla */
  }
  return 1U;
}

/* Ana döngüden her turda çağrılır; ASSIST_RAMP_TICK_MS'de bir rampayı ilerletir (rot_service
 * ile aynı mantık). Fark: önceki ARR/CMP yazımının ARROK+CMPOK bayrakları gelmeden yeni yazım
 * yapılmaz (o tur atlanır); bayraklar ASSIST_HW_TIMEOUT_MS içinde gelmezse eksen durdurulur. */
static void assist_service(void)
{
  uint32_t now = HAL_GetTick();
  uint32_t dt;
  uint32_t goal;
  const uint32_t both = LPTIM_ISR_ARROK | LPTIM_ISR_CMPOK;

  if (!g_assist.pulsing) {
    return;
  }

  if (g_assist.reg_pending) {
    if ((LPTIM1->ISR & both) == both) {
      LPTIM1->ICR = LPTIM_ICR_ARROKCF | LPTIM_ICR_CMPOKCF;
      g_assist.reg_pending = 0U;
    } else {
      if ((now - g_assist.reg_write_ms) > ASSIST_HW_TIMEOUT_MS) {
        assist_stop();                       /* donanım yanıt vermiyor: güvenli tarafa */
      }
      return;
    }
  }

  dt = now - g_assist.last_ramp_ms;
  if (dt < ASSIST_RAMP_TICK_MS) {
    return;
  }
  g_assist.last_ramp_ms = now;
  if (dt > 100U) dt = 100U;                  /* uzun duraksamada tek seferde büyük sıçrama olmasın */

  goal = g_assist.reversing ? ASSIST_RAMP_START_DELAY_US : g_assist.target_delay_us;

  if (g_assist.cur_delay_us != goal) {
    g_assist.cur_delay_us = ramp_next_delay(g_assist.cur_delay_us, goal, dt, ASSIST_RAMP_ACCEL_HZ_PER_S);
    assist_write_delay(g_assist.cur_delay_us);
    g_assist.reg_pending  = 1U;
    g_assist.reg_write_ms = now;
  }

  if (g_assist.reversing && g_assist.cur_delay_us >= ASSIST_RAMP_START_DELAY_US) {
    assist_halt_pulses();                    /* START hızına indi: DIR'i çevir, yeniden kalk */
    if (!assist_begin(g_assist.state)) {
      assist_stop();
    }
  }
}

/* ==========================================================================
 *  JSON  —  kütüphanesiz, sadece ihtiyacımız olan kadar basit ayrıştırıcı
 * ========================================================================== */

/* {"delay":500} içinden 500'ü çeker. Bulursa 1, bulamazsa 0 döner. */
static int json_read_int(const char *json, const char *key, int32_t *out)
{
  char pattern[24];
  const char *p;

  snprintf(pattern, sizeof(pattern), "\"%s\"", key);
  p = strstr(json, pattern);
  if (p == NULL) return 0;

  p = strchr(p, ':');
  if (p == NULL) return 0;

  *out = (int32_t)strtol(p + 1, NULL, 10);
  return 1;
}

/* {"cmd":"step"} içinden step'i çeker. */
static int json_read_str(const char *json, const char *key, char *out, uint16_t out_size)
{
  char pattern[24];
  const char *p;
  uint16_t i = 0;

  snprintf(pattern, sizeof(pattern), "\"%s\"", key);
  p = strstr(json, pattern);
  if (p == NULL) return 0;

  p = strchr(p + strlen(pattern), ':');
  if (p == NULL) return 0;

  p = strchr(p, '"');          /* değerin açılış tırnağı */
  if (p == NULL) return 0;
  p++;

  while (*p != '\0' && *p != '"' && i < (out_size - 1U)) {
    out[i++] = *p++;
  }
  out[i] = '\0';
  return 1;
}

/* ==========================================================================
 *  SERİ PORT  —  gönderme ve komut işleme
 * ========================================================================== */

static void uart_send(const char *s)
{
  HAL_UART_Transmit(&huart2, (uint8_t *)s, (uint16_t)strlen(s), 100);
}

static void send_status(void)
{
  char buf[240];   /* en kötü durum (tüm sayılar maksimum basamak) 193 karakter */

  snprintf(buf, sizeof(buf),
           "{\"t\":%lu,\"e1\":%ld,\"e2\":%ld,\"um1\":%ld,\"um2\":%ld,"
           "\"remaining\":%lu,\"running\":%u,\"dc\":%u,\"dcSpeed\":%u,"
           "\"rot\":%u,\"rdelay\":%lu,\"assist\":%u,\"adelay\":%lu}\r\n",
           (unsigned long)HAL_GetTick(),
           (long)g_enc1.total,
           (long)g_enc2.total,
           (long)encoder_to_micrometers(g_enc1.total),
           (long)encoder_to_micrometers(g_enc2.total),
           (unsigned long)g_step.remaining,
           (unsigned)g_step.running,
           (unsigned)g_dc_state,
           (unsigned)g_dc_speed,
           (unsigned)g_rot.state,
           (unsigned long)((g_rot.state == 0U) ? 0U : g_rot.target_delay_us),
           (unsigned)g_assist.state,
           (unsigned long)((g_assist.state == 0U) ? 0U : g_assist.target_delay_us));

  uart_send(buf);
}

static void process_command(const char *line)
{
  char    cmd[16];
  char    dir_str[12];
  int32_t dir_i = 0, delay_i = 500, steps_i = 0, accel_i = 0;
  int32_t speed_i = (int32_t)DC_SPEED_DEFAULT_PCT;

  if (!json_read_str(line, "cmd", cmd, sizeof(cmd))) {
    uart_send("{\"err\":\"missing cmd field\"}\r\n");
    return;
  }

  /* Geçerli bir komut satırı ayrıştırıldı — karşı tarafın gerçekten bizimle
   * konuştuğu kanıtlandı. LED yanıp sönme hızını buna göre değiştiriyoruz
   * (bkz. USER CODE 3). "bye" hariç her komutta 1'e set edilir; "bye" kendi
   * branch'inde bunu hemen ardından tekrar 0'a çeker (host bağlantıyı kapattı). */
  g_host_confirmed = 1;

  /* ---- Step motoru hareket ettir ---- */
  if (strcmp(cmd, "step") == 0) {
    json_read_int(line, "dir",   &dir_i);
    json_read_int(line, "delay", &delay_i);
    json_read_int(line, "steps", &steps_i);
    json_read_int(line, "accel", &accel_i);  /* opsiyonel - yoksa 0 (rampasız, eski davranış) */

    if (steps_i <= 0) {
      uart_send("{\"err\":\"steps must be > 0\"}\r\n");
      return;
    }
    if (accel_i < 0) accel_i = 0;
    step_start((uint8_t)(dir_i ? 1 : 0), (uint32_t)steps_i, (uint32_t)delay_i, (uint32_t)accel_i);
    uart_send("{\"ok\":\"step\"}\r\n");
  }

  /* ---- Step motoru anında durdur ---- */
  else if (strcmp(cmd, "stop") == 0) {
    step_stop();
    rot_stop();      /* dönüş ekseni de durur (sözleşme: stop/reset/bye rot'u keser) */
    assist_stop();   /* yardımcı çift de durur (aynı sözleşme) */
    uart_send("{\"ok\":\"stop\"}\r\n");
  }

  /* ---- DC motor ---- */
  else if (strcmp(cmd, "dc") == 0) {
    if (!json_read_str(line, "dir", dir_str, sizeof(dir_str))) {
      uart_send("{\"err\":\"missing dir field\"}\r\n");
      return;
    }
    /* "speed" opsiyonel - yoksa DC_SPEED_DEFAULT_PCT (100 = eski tam-hız
     * davranışı, geriye dönük uyumlu). 0-100 dışına taşarsa dc_set() kırpar. */
    json_read_int(line, "speed", &speed_i);
    /* uint8_t'ye cast etmeden ÖNCE 0-100'e kırp - yoksa ör. speed=300
     * cast sırasında sarıp (300 mod 256 = 44) yanlış bir hıza dönüşür. */
    if (speed_i < 0)   speed_i = 0;
    if (speed_i > 100) speed_i = 100;

    if      (strcmp(dir_str, "forward")  == 0) dc_set(1, (uint8_t)speed_i);
    else if (strcmp(dir_str, "backward") == 0) dc_set(2, (uint8_t)speed_i);
    else                                        dc_set(0, 0);
    uart_send("{\"ok\":\"dc\"}\r\n");
  }

  /* ---- Dönüş ekseni (NEMA17 + TB6600): sürekli döndür / hız-yön güncelle / durdur ----
   * {"cmd":"rot","dir":"cw"|"ccw","delay":<us>} ve {"cmd":"rot","dir":"stop"}.
   * delay aralık dışıysa rot_command() sessizce kırpar (step ile aynı). Bilinmeyen
   * dir değeri hata döner VE ekseni durdurur (fail-safe). */
  else if (strcmp(cmd, "rot") == 0) {
    if (!json_read_str(line, "dir", dir_str, sizeof(dir_str))) {
      uart_send("{\"err\":\"missing dir field\"}\r\n");
      return;
    }

    if (strcmp(dir_str, "stop") == 0) {
      rot_stop();
    } else if (strcmp(dir_str, "cw") == 0 || strcmp(dir_str, "ccw") == 0) {
      if (!json_read_int(line, "delay", &delay_i)) {
        uart_send("{\"err\":\"missing delay field\"}\r\n");
        return;
      }
      /* uint32_t'ye çevirmeden ÖNCE kırp: negatif delay sarıp dev bir sayıya dönmesin */
      if (delay_i < (int32_t)ROT_MIN_DELAY_US) delay_i = (int32_t)ROT_MIN_DELAY_US;
      rot_command((strcmp(dir_str, "cw") == 0) ? 1U : 2U, (uint32_t)delay_i);
    } else {
      rot_stop();
      uart_send("{\"err\":\"invalid dir\"}\r\n");
      return;
    }
    uart_send("{\"ok\":\"rot\"}\r\n");
  }

  /* ---- Yardımcı çift (2x NEMA17 + 2. TB6600): sürekli döndür / hız-yön güncelle / durdur ----
   * {"cmd":"assist","dir":"cw"|"ccw","delay":<us>} ve {"cmd":"assist","dir":"stop"}.
   * rot ile birebir aynı sözleşme (delay kırpma, invalid dir = durdur + hata). Ek hata:
   * LPTIM1 yazma bayrağı gelmezse eksen durdurulur ve "assist timer fault" döner. */
  else if (strcmp(cmd, "assist") == 0) {
    if (!json_read_str(line, "dir", dir_str, sizeof(dir_str))) {
      uart_send("{\"err\":\"missing dir field\"}\r\n");
      return;
    }

    if (strcmp(dir_str, "stop") == 0) {
      assist_stop();
    } else if (strcmp(dir_str, "cw") == 0 || strcmp(dir_str, "ccw") == 0) {
      if (!json_read_int(line, "delay", &delay_i)) {
        uart_send("{\"err\":\"missing delay field\"}\r\n");
        return;
      }
      /* uint32_t'ye çevirmeden ÖNCE kırp: negatif delay sarıp dev bir sayıya dönmesin */
      if (delay_i < (int32_t)ASSIST_MIN_DELAY_US) delay_i = (int32_t)ASSIST_MIN_DELAY_US;
      if (!assist_command((strcmp(dir_str, "cw") == 0) ? 1U : 2U, (uint32_t)delay_i)) {
        uart_send("{\"err\":\"assist timer fault\"}\r\n");
        return;
      }
    } else {
      assist_stop();
      uart_send("{\"err\":\"invalid dir\"}\r\n");
      return;
    }
    uart_send("{\"ok\":\"assist\"}\r\n");
  }

  /* ---- Encoder sayaçlarını sıfırla ---- */
  else if (strcmp(cmd, "reset") == 0) {
    rot_stop();      /* sözleşme: reset de dönüş eksenini durdurur */
    assist_stop();   /* ... ve yardımcı çifti */
    encoder_reset(&g_enc1);
    encoder_reset(&g_enc2);
    uart_send("{\"ok\":\"reset\"}\r\n");
  }

  /* ---- Bağlantı testi ---- */
  else if (strcmp(cmd, "ping") == 0) {
    uart_send("{\"ok\":\"pong\"}\r\n");
  }

  /* ---- Host bağlantıyı kapattı: LED'i yavaş moda döndür (22-09-2026) ----
   * Pi kendi bağlantı-sağlığı mantığıyla (heartbeat/timeout) kopmaya karar
   * verince bunu gönderir. stop/reset/ping gibi hiçbir gate'e bağlı değil,
   * her zaman işlenir. */
  else if (strcmp(cmd, "bye") == 0) {
    rot_stop();      /* host koptu: dönüş ekseni kontrolsüz dönmesin */
    assist_stop();   /* ... yardımcı çift de */
    g_host_confirmed = 0;
    uart_send("{\"ok\":\"bye\"}\r\n");
  }

  else {
    uart_send("{\"err\":\"unknown cmd\"}\r\n");
  }
}

/* USER CODE END 0 */

int main(void)
{

  /* MCU Configuration--------------------------------------------------------*/

  /* Reset of all peripherals, Initializes the Flash interface and the Systick. */
  HAL_Init();

  /* Configure the system clock */
  SystemClock_Config();

  /* Initialize all configured peripherals */
  MX_GPIO_Init();
  MX_TIM1_Init();
  MX_LPTIM1_Init();
  MX_TIM2_Init();
  MX_TIM3_Init();
  MX_TIM14_Init();
  MX_TIM16_Init();
  MX_TIM17_Init();
  MX_USART2_UART_Init();
  /* USER CODE BEGIN 2 */

  /* Motor çıkışlarını güvenli başlangıç durumuna al */
  HAL_GPIO_WritePin(STEP_GPIO_Port,   STEP_Pin,   GPIO_PIN_RESET);
  HAL_GPIO_WritePin(DIR_GPIO_Port,    DIR_Pin,    GPIO_PIN_RESET);
  HAL_GPIO_WritePin(ROT_DIR_GPIO_Port, ROT_DIR_Pin, GPIO_PIN_RESET);
  HAL_GPIO_WritePin(ASSIST_DIR_GPIO_Port, ASSIST_DIR_Pin, GPIO_PIN_RESET);

  /* DC motor PWM kanallarını 0% duty (dur) ile başlat - PB8/PB9 artık plain
   * GPIO değil, TIM16_CH1/TIM17_CH1 AF-PWM modunda (bkz. MX_TIM16/17_Init). */
  HAL_TIM_PWM_Start(&htim16, TIM_CHANNEL_1);
  HAL_TIM_PWM_Start(&htim17, TIM_CHANNEL_1);
  __HAL_TIM_SET_COMPARE(&htim16, TIM_CHANNEL_1, 0U);
  __HAL_TIM_SET_COMPARE(&htim17, TIM_CHANNEL_1, 0U);

  /* Dönüş ekseni PUL (TIM2_CH1/PA0): 0 duty (CCR=0 -> sürekli LOW) ile başlat,
   * darbe ancak "rot" komutuyla çıkar. Sayaç sürekli çalışır, durdurma = CCR=0. */
  HAL_TIM_PWM_Start(&htim2, TIM_CHANNEL_1);
  __HAL_TIM_SET_COMPARE(&htim2, TIM_CHANNEL_1, 0U);

  /* Yardımcı çift PUL (LPTIM1_OUT/PB0): açılışta PB0 GPIO LOW, LPTIM1 sıfır (kapalı);
   * darbe ancak "assist" komutuyla çıkar. */
  assist_halt_pulses();

  /* İki encoder'ın donanım sayacını başlat */
  encoder_init(&g_enc1, &htim1);   /* Encoder 1 - motorlu tekerlek  (PA8 / PA9) */
  encoder_init(&g_enc2, &htim3);   /* Encoder 2 - boşta tekerlek    (PA6 / PA7) */

  /* Seri porttan ilk karakteri beklemeye başla (bundan sonrası kesmede zincirlenir) */
  HAL_UART_Receive_IT(&huart2, &g_rx_byte, 1);

  uart_send("{\"ok\":\"feedvision test firmware ready\"}\r\n");

  g_last_status_ms = HAL_GetTick();

  /* USER CODE END 2 */

  /* Infinite loop */
  while (1)
  {

    /* USER CODE BEGIN 3 */

    /* --- 1) PC'den tam bir komut satırı geldiyse işle --- */
    if (g_command_ready) {
      char copy[RX_LINE_MAX];
      strncpy(copy, g_command, sizeof(copy) - 1U);
      copy[sizeof(copy) - 1U] = '\0';
      g_command_ready = 0;              /* kopyaladıktan SONRA temizle */
      process_command(copy);
    }

    /* --- 1b) Dönüş ekseni rampasını ilerlet (çalışmıyorsa hemen döner) --- */
    rot_service();

    /* --- 1c) Yardımcı çift rampasını ilerlet (çalışmıyorsa hemen döner) --- */
    assist_service();

    /* --- 2) Her 50 ms'de bir encoder'ları oku ve durumu PC'ye gönder --- */
    if ((HAL_GetTick() - g_last_status_ms) >= STATUS_PERIOD_MS) {
      g_last_status_ms = HAL_GetTick();

      encoder_update(&g_enc1);
      encoder_update(&g_enc2);
      send_status();

      /* Kart üstündeki LED (LD3) bağlantı durumunu gösterir:
       *   - g_host_confirmed=0 (henüz kimse konuşmadı): her 10 tikte bir
       *     yanıp söner -> ~1 Hz, yavaş "hayattayım" darbesi.
       *   - g_host_confirmed=1 (Pi/Mac'ten en az bir geçerli komut geldi):
       *     her tikte yanıp söner -> ~10 Hz, hızlı "bağlantı doğrulandı"
       *     darbesi. Bu döngü 50 ms'de bir çalıştığı için (STATUS_PERIOD_MS)
       *     10 tik = 500 ms = 1 Hz, 1 tik = 100 ms = 10 Hz eder. */
      g_led_tick++;
      {
        uint16_t toggle_every = g_host_confirmed ? 1U : 10U;
        if ((g_led_tick % toggle_every) == 0U) {
#ifdef LD3_GPIO_Port
          HAL_GPIO_TogglePin(LD3_GPIO_Port, LD3_Pin);
#endif
        }
      }
    }

  }
  /* USER CODE END 3 */
}

void SystemClock_Config(void)
{
  RCC_OscInitTypeDef RCC_OscInitStruct = {0};
  RCC_ClkInitTypeDef RCC_ClkInitStruct = {0};

  /** Configure the main internal regulator output voltage
  */
  HAL_PWREx_ControlVoltageScaling(PWR_REGULATOR_VOLTAGE_SCALE1);

  /** Initializes the RCC Oscillators according to the specified parameters
  * in the RCC_OscInitTypeDef structure.
  */
  RCC_OscInitStruct.OscillatorType = RCC_OSCILLATORTYPE_HSI;
  RCC_OscInitStruct.HSIState = RCC_HSI_ON;
  RCC_OscInitStruct.HSIDiv = RCC_HSI_DIV1;
  RCC_OscInitStruct.HSICalibrationValue = RCC_HSICALIBRATION_DEFAULT;
  RCC_OscInitStruct.PLL.PLLState = RCC_PLL_ON;
  RCC_OscInitStruct.PLL.PLLSource = RCC_PLLSOURCE_HSI;
  RCC_OscInitStruct.PLL.PLLM = RCC_PLLM_DIV1;
  RCC_OscInitStruct.PLL.PLLN = 8;
  RCC_OscInitStruct.PLL.PLLP = RCC_PLLP_DIV2;
  RCC_OscInitStruct.PLL.PLLQ = RCC_PLLQ_DIV2;
  RCC_OscInitStruct.PLL.PLLR = RCC_PLLR_DIV2;
  if (HAL_RCC_OscConfig(&RCC_OscInitStruct) != HAL_OK)
  {
    Error_Handler();
  }

  /** Initializes the CPU, AHB and APB buses clocks
  */
  RCC_ClkInitStruct.ClockType = RCC_CLOCKTYPE_HCLK|RCC_CLOCKTYPE_SYSCLK
                              |RCC_CLOCKTYPE_PCLK1;
  RCC_ClkInitStruct.SYSCLKSource = RCC_SYSCLKSOURCE_PLLCLK;
  RCC_ClkInitStruct.AHBCLKDivider = RCC_SYSCLK_DIV1;
  RCC_ClkInitStruct.APB1CLKDivider = RCC_HCLK_DIV1;

  if (HAL_RCC_ClockConfig(&RCC_ClkInitStruct, FLASH_LATENCY_2) != HAL_OK)
  {
    Error_Handler();
  }
}

static void MX_TIM1_Init(void)
{

  TIM_Encoder_InitTypeDef sConfig = {0};
  TIM_MasterConfigTypeDef sMasterConfig = {0};

  htim1.Instance = TIM1;
  htim1.Init.Prescaler = 0;
  htim1.Init.CounterMode = TIM_COUNTERMODE_UP;
  htim1.Init.Period = 65535;
  htim1.Init.ClockDivision = TIM_CLOCKDIVISION_DIV1;
  htim1.Init.RepetitionCounter = 0;
  htim1.Init.AutoReloadPreload = TIM_AUTORELOAD_PRELOAD_DISABLE;
  sConfig.EncoderMode = TIM_ENCODERMODE_TI12;
  sConfig.IC1Polarity = TIM_ICPOLARITY_RISING;
  sConfig.IC1Selection = TIM_ICSELECTION_DIRECTTI;
  sConfig.IC1Prescaler = TIM_ICPSC_DIV1;
  sConfig.IC1Filter = 15;
  sConfig.IC2Polarity = TIM_ICPOLARITY_RISING;
  sConfig.IC2Selection = TIM_ICSELECTION_DIRECTTI;
  sConfig.IC2Prescaler = TIM_ICPSC_DIV1;
  sConfig.IC2Filter = 15;
  if (HAL_TIM_Encoder_Init(&htim1, &sConfig) != HAL_OK)
  {
    Error_Handler();
  }
  sMasterConfig.MasterOutputTrigger = TIM_TRGO_RESET;
  sMasterConfig.MasterOutputTrigger2 = TIM_TRGO2_RESET;
  sMasterConfig.MasterSlaveMode = TIM_MASTERSLAVEMODE_DISABLE;
  if (HAL_TIMEx_MasterConfigSynchronization(&htim1, &sMasterConfig) != HAL_OK)
  {
    Error_Handler();
  }

}

static void MX_LPTIM1_Init(void)
{
  __HAL_RCC_LPTIM1_CONFIG(RCC_LPTIM1CLKSOURCE_PCLK1);
  __HAL_RCC_LPTIM1_CLK_ENABLE();
}

static void MX_TIM2_Init(void)
{
  TIM_ClockConfigTypeDef sClockSourceConfig = {0};
  TIM_MasterConfigTypeDef sMasterConfig = {0};
  TIM_OC_InitTypeDef sConfigOC = {0};

  htim2.Instance = TIM2;
  htim2.Init.Prescaler = ROT_PWM_PRESCALER;
  htim2.Init.CounterMode = TIM_COUNTERMODE_UP;
  htim2.Init.Period = ROT_PWM_INIT_PERIOD_TICKS;
  htim2.Init.ClockDivision = TIM_CLOCKDIVISION_DIV1;
  htim2.Init.AutoReloadPreload = TIM_AUTORELOAD_PRELOAD_ENABLE;
  if (HAL_TIM_Base_Init(&htim2) != HAL_OK)
  {
    Error_Handler();
  }
  sClockSourceConfig.ClockSource = TIM_CLOCKSOURCE_INTERNAL;
  if (HAL_TIM_ConfigClockSource(&htim2, &sClockSourceConfig) != HAL_OK)
  {
    Error_Handler();
  }
  if (HAL_TIM_PWM_Init(&htim2) != HAL_OK)
  {
    Error_Handler();
  }
  sMasterConfig.MasterOutputTrigger = TIM_TRGO_RESET;
  sMasterConfig.MasterSlaveMode = TIM_MASTERSLAVEMODE_DISABLE;
  if (HAL_TIMEx_MasterConfigSynchronization(&htim2, &sMasterConfig) != HAL_OK)
  {
    Error_Handler();
  }
  sConfigOC.OCMode = TIM_OCMODE_PWM1;
  sConfigOC.Pulse = 0;                       /* başlangıç duty = 0 (dur) */
  sConfigOC.OCPolarity = TIM_OCPOLARITY_HIGH;
  sConfigOC.OCFastMode = TIM_OCFAST_DISABLE;
  if (HAL_TIM_PWM_ConfigChannel(&htim2, &sConfigOC, TIM_CHANNEL_1) != HAL_OK)
  {
    Error_Handler();
  }
  HAL_TIM_MspPostInit(&htim2);   /* PA0 -> TIM2_CH1 AF2 (stm32g0xx_hal_msp.c) */
}

static void MX_TIM3_Init(void)
{

  TIM_Encoder_InitTypeDef sConfig = {0};
  TIM_MasterConfigTypeDef sMasterConfig = {0};

  htim3.Instance = TIM3;
  htim3.Init.Prescaler = 0;
  htim3.Init.CounterMode = TIM_COUNTERMODE_UP;
  htim3.Init.Period = 65535;
  htim3.Init.ClockDivision = TIM_CLOCKDIVISION_DIV1;
  htim3.Init.AutoReloadPreload = TIM_AUTORELOAD_PRELOAD_DISABLE;
  sConfig.EncoderMode = TIM_ENCODERMODE_TI12;
  sConfig.IC1Polarity = TIM_ICPOLARITY_RISING;
  sConfig.IC1Selection = TIM_ICSELECTION_DIRECTTI;
  sConfig.IC1Prescaler = TIM_ICPSC_DIV1;
  sConfig.IC1Filter = 15;
  sConfig.IC2Polarity = TIM_ICPOLARITY_RISING;
  sConfig.IC2Selection = TIM_ICSELECTION_DIRECTTI;
  sConfig.IC2Prescaler = TIM_ICPSC_DIV1;
  sConfig.IC2Filter = 15;
  if (HAL_TIM_Encoder_Init(&htim3, &sConfig) != HAL_OK)
  {
    Error_Handler();
  }
  sMasterConfig.MasterOutputTrigger = TIM_TRGO_RESET;
  sMasterConfig.MasterSlaveMode = TIM_MASTERSLAVEMODE_DISABLE;
  if (HAL_TIMEx_MasterConfigSynchronization(&htim3, &sMasterConfig) != HAL_OK)
  {
    Error_Handler();
  }

}

static void MX_TIM14_Init(void)
{
  htim14.Instance = TIM14;
  htim14.Init.Prescaler = 63;
  htim14.Init.CounterMode = TIM_COUNTERMODE_UP;
  htim14.Init.Period = 499;
  htim14.Init.ClockDivision = TIM_CLOCKDIVISION_DIV1;
  htim14.Init.RepetitionCounter = 0;
  htim14.Init.AutoReloadPreload = TIM_AUTORELOAD_PRELOAD_DISABLE;
  if (HAL_TIM_Base_Init(&htim14) != HAL_OK)
  {
    Error_Handler();
  }
}

static void MX_TIM16_Init(void)
{
  TIM_OC_InitTypeDef sConfigOC = {0};

  htim16.Instance = TIM16;
  htim16.Init.Prescaler = DC_PWM_PRESCALER;
  htim16.Init.CounterMode = TIM_COUNTERMODE_UP;
  htim16.Init.Period = DC_PWM_PERIOD_TICKS;
  htim16.Init.ClockDivision = TIM_CLOCKDIVISION_DIV1;
  htim16.Init.RepetitionCounter = 0;
  htim16.Init.AutoReloadPreload = TIM_AUTORELOAD_PRELOAD_DISABLE;
  if (HAL_TIM_PWM_Init(&htim16) != HAL_OK)
  {
    Error_Handler();
  }

  sConfigOC.OCMode       = TIM_OCMODE_PWM1;
  sConfigOC.Pulse        = 0;                  /* başlangıç duty = 0 (dur) */
  sConfigOC.OCPolarity   = TIM_OCPOLARITY_HIGH;
  sConfigOC.OCNPolarity  = TIM_OCNPOLARITY_HIGH;
  sConfigOC.OCFastMode   = TIM_OCFAST_DISABLE;
  sConfigOC.OCIdleState  = TIM_OCIDLESTATE_RESET;
  sConfigOC.OCNIdleState = TIM_OCNIDLESTATE_RESET;
  if (HAL_TIM_PWM_ConfigChannel(&htim16, &sConfigOC, TIM_CHANNEL_1) != HAL_OK)
  {
    Error_Handler();
  }
}

static void MX_TIM17_Init(void)
{
  TIM_OC_InitTypeDef sConfigOC = {0};

  htim17.Instance = TIM17;
  htim17.Init.Prescaler = DC_PWM_PRESCALER;
  htim17.Init.CounterMode = TIM_COUNTERMODE_UP;
  htim17.Init.Period = DC_PWM_PERIOD_TICKS;
  htim17.Init.ClockDivision = TIM_CLOCKDIVISION_DIV1;
  htim17.Init.RepetitionCounter = 0;
  htim17.Init.AutoReloadPreload = TIM_AUTORELOAD_PRELOAD_DISABLE;
  if (HAL_TIM_PWM_Init(&htim17) != HAL_OK)
  {
    Error_Handler();
  }

  sConfigOC.OCMode       = TIM_OCMODE_PWM1;
  sConfigOC.Pulse        = 0;                  /* başlangıç duty = 0 (dur) */
  sConfigOC.OCPolarity   = TIM_OCPOLARITY_HIGH;
  sConfigOC.OCNPolarity  = TIM_OCNPOLARITY_HIGH;
  sConfigOC.OCFastMode   = TIM_OCFAST_DISABLE;
  sConfigOC.OCIdleState  = TIM_OCIDLESTATE_RESET;
  sConfigOC.OCNIdleState = TIM_OCNIDLESTATE_RESET;
  if (HAL_TIM_PWM_ConfigChannel(&htim17, &sConfigOC, TIM_CHANNEL_1) != HAL_OK)
  {
    Error_Handler();
  }
}

static void MX_USART2_UART_Init(void)
{

  huart2.Instance = USART2;
  huart2.Init.BaudRate = 115200;
  huart2.Init.WordLength = UART_WORDLENGTH_8B;
  huart2.Init.StopBits = UART_STOPBITS_1;
  huart2.Init.Parity = UART_PARITY_NONE;
  huart2.Init.Mode = UART_MODE_TX_RX;
  huart2.Init.HwFlowCtl = UART_HWCONTROL_NONE;
  huart2.Init.OverSampling = UART_OVERSAMPLING_16;
  huart2.Init.OneBitSampling = UART_ONE_BIT_SAMPLE_DISABLE;
  huart2.Init.ClockPrescaler = UART_PRESCALER_DIV1;
  huart2.AdvancedInit.AdvFeatureInit = UART_ADVFEATURE_NO_INIT;
  if (HAL_UART_Init(&huart2) != HAL_OK)
  {
    Error_Handler();
  }

}

static void MX_GPIO_Init(void)
{
  GPIO_InitTypeDef GPIO_InitStruct = {0};

  /* GPIO Ports Clock Enable */
  __HAL_RCC_GPIOB_CLK_ENABLE();
  __HAL_RCC_GPIOC_CLK_ENABLE();
  __HAL_RCC_GPIOF_CLK_ENABLE();
  __HAL_RCC_GPIOA_CLK_ENABLE();

  /*Configure GPIO pin Output Level */
  HAL_GPIO_WritePin(GPIOB, DIR_Pin, GPIO_PIN_RESET);

  /*Configure GPIO pin Output Level */
  HAL_GPIO_WritePin(ROT_DIR_GPIO_Port, ROT_DIR_Pin, GPIO_PIN_RESET);

  /*Configure GPIO pin Output Level */
  HAL_GPIO_WritePin(GPIOB, ASSIST_PUL_Pin|ASSIST_DIR_Pin, GPIO_PIN_RESET);

  /*Configure GPIO pin Output Level */
  HAL_GPIO_WritePin(LD3_GPIO_Port, LD3_Pin, GPIO_PIN_RESET);

  /*Configure GPIO pin Output Level */
  HAL_GPIO_WritePin(STEP_GPIO_Port, STEP_Pin, GPIO_PIN_RESET);

  /*Configure GPIO pin : DIR_Pin
   * NOT: DC_IB1_Pin (PB9) ve DC_IA1_Pin (PB8) burada YOK - artık plain GPIO
   * değiller, TIM16_CH1/TIM17_CH1 AF-PWM modunda (bkz. HAL_TIM_PWM_MspInit,
   * stm32g0xx_hal_msp.c). 22-09-2026, backlog #109. */
  GPIO_InitStruct.Pin = DIR_Pin;
  GPIO_InitStruct.Mode = GPIO_MODE_OUTPUT_PP;
  GPIO_InitStruct.Pull = GPIO_NOPULL;
  GPIO_InitStruct.Speed = GPIO_SPEED_FREQ_HIGH;
  HAL_GPIO_Init(GPIOB, &GPIO_InitStruct);

  /*Configure GPIO pin : ROT_DIR_Pin (dönüş ekseni DIR, 05-10-2026; PUL=PA0 TIM2_CH1 AF-PWM, bkz. HAL_TIM_PWM_MspInit) */
  GPIO_InitStruct.Pin = ROT_DIR_Pin;
  GPIO_InitStruct.Mode = GPIO_MODE_OUTPUT_PP;
  GPIO_InitStruct.Pull = GPIO_NOPULL;
  GPIO_InitStruct.Speed = GPIO_SPEED_FREQ_HIGH;
  HAL_GPIO_Init(ROT_DIR_GPIO_Port, &GPIO_InitStruct);

  /*Configure GPIO pins : ASSIST_PUL_Pin ASSIST_DIR_Pin (yardımcı çift, 2. TB6600).
   * PB0 açılışta düz GPIO LOW; "assist" komutunda assist_pul_af() ile LPTIM1_OUT'a (AF5)
   * geçer, durdurmada tekrar GPIO LOW. */
  GPIO_InitStruct.Pin = ASSIST_PUL_Pin|ASSIST_DIR_Pin;
  GPIO_InitStruct.Mode = GPIO_MODE_OUTPUT_PP;
  GPIO_InitStruct.Pull = GPIO_NOPULL;
  GPIO_InitStruct.Speed = GPIO_SPEED_FREQ_HIGH;
  HAL_GPIO_Init(GPIOB, &GPIO_InitStruct);

  /*Configure GPIO pin : T_NRST_Pin */
  GPIO_InitStruct.Pin = T_NRST_Pin;
  GPIO_InitStruct.Mode = GPIO_MODE_IT_RISING;
  GPIO_InitStruct.Pull = GPIO_NOPULL;
  HAL_GPIO_Init(T_NRST_GPIO_Port, &GPIO_InitStruct);

  /*Configure GPIO pin : LD3_Pin */
  GPIO_InitStruct.Pin = LD3_Pin;
  GPIO_InitStruct.Mode = GPIO_MODE_OUTPUT_PP;
  GPIO_InitStruct.Pull = GPIO_NOPULL;
  GPIO_InitStruct.Speed = GPIO_SPEED_FREQ_LOW;
  HAL_GPIO_Init(LD3_GPIO_Port, &GPIO_InitStruct);

  /*Configure GPIO pin : STEP_Pin */
  GPIO_InitStruct.Pin = STEP_Pin;
  GPIO_InitStruct.Mode = GPIO_MODE_OUTPUT_PP;
  GPIO_InitStruct.Pull = GPIO_NOPULL;
  GPIO_InitStruct.Speed = GPIO_SPEED_FREQ_HIGH;
  HAL_GPIO_Init(STEP_GPIO_Port, &GPIO_InitStruct);

}

/* USER CODE BEGIN 4 */

/* --------------------------------------------------------------------------
 * TIM14 kesmesi: step darbesini üreten yer (22-09-2026'dan önce TIM16'daydı).
 * Her çağrılışında pini bir kez değiştirir. İki çağrı = bir tam darbe.
 * Burada uzun iş yapılmaz (printf, HAL_Delay vb. YASAK) - zamanlama bozulur.
 * -------------------------------------------------------------------------- */
void HAL_TIM_PeriodElapsedCallback(TIM_HandleTypeDef *htim)
{
  if (htim->Instance != TIM14) {
    return;
  }

  if (!g_step.running) {
    HAL_TIM_Base_Stop_IT(&htim14);
    return;
  }

  if (g_step.level == 0U) {
    /* Darbenin yükselen kenarı - sürücü adımı burada atar */
    HAL_GPIO_WritePin(STEP_GPIO_Port, STEP_Pin, GPIO_PIN_SET);
    g_step.level = 1U;
  } else {
    /* Darbenin düşen kenarı - bir darbe tamamlandı */
    HAL_GPIO_WritePin(STEP_GPIO_Port, STEP_Pin, GPIO_PIN_RESET);
    g_step.level = 0U;

    if (g_step.remaining > 0U) {
      g_step.remaining--;
    }
    if (g_step.remaining == 0U) {
      g_step.running = 0U;
      HAL_TIM_Base_Stop_IT(&htim14);
    } else {
      /* Rampa varsa (accel_steps>0) sıradaki darbenin hızı bir öncekinden
       * farklı olabilir - her darbede yeniden hesaplayıp timer'a yazıyoruz.
       * Rampasız harekette (accel_steps=0) bu hep aynı değeri döndürür,
       * gereksiz ama zararsız bir yazma. */
      __HAL_TIM_SET_AUTORELOAD(&htim14, (step_delay_for_remaining(g_step.remaining) / 2U) - 1U);
    }
  }
}

/* --------------------------------------------------------------------------
 * USART2 kesmesi: PC'den gelen karakterleri satır olacak şekilde biriktirir.
 * -------------------------------------------------------------------------- */
void HAL_UART_RxCpltCallback(UART_HandleTypeDef *huart)
{
  if (huart->Instance != USART2) {
    return;
  }

  char c = (char)g_rx_byte;

  if (c == '\n' || c == '\r') {
    /* Satır bitti - ana döngü önceki komutu henüz almadıysa bunu atla */
    if ((g_rx_length > 0U) && (g_command_ready == 0U)) {
      memcpy(g_command, g_rx_line, g_rx_length);
      g_command[g_rx_length] = '\0';
      g_command_ready = 1U;
    }
    g_rx_length = 0U;
  } else if (g_rx_length < (RX_LINE_MAX - 1U)) {
    g_rx_line[g_rx_length++] = c;
  } else {
    g_rx_length = 0U;   /* satır çok uzun - baştan başla */
  }

  /* Bir sonraki karakteri beklemeye devam et */
  HAL_UART_Receive_IT(&huart2, &g_rx_byte, 1);
}

/* --------------------------------------------------------------------------
 * USART2 hata kesmesi.
 * Bu fonksiyon OLMAZSA: seri portta tek bir "overrun" hatası olduğunda HAL
 * dinlemeyi tamamen bırakır ve kart bir daha hiçbir komut duymaz. Burada
 * dinlemeyi yeniden başlatarak bunu engelliyoruz.
 * -------------------------------------------------------------------------- */
void HAL_UART_ErrorCallback(UART_HandleTypeDef *huart)
{
  if (huart->Instance != USART2) {
    return;
  }

  __HAL_UART_CLEAR_OREFLAG(huart);
  __HAL_UART_CLEAR_NEFLAG(huart);
  __HAL_UART_CLEAR_FEFLAG(huart);
  __HAL_UART_CLEAR_PEFLAG(huart);

  g_rx_length = 0U;
  HAL_UART_Receive_IT(&huart2, &g_rx_byte, 1);
}

/* USER CODE END 4 */

void Error_Handler(void)
{
  __disable_irq();
  while (1)
  {
  }
}
